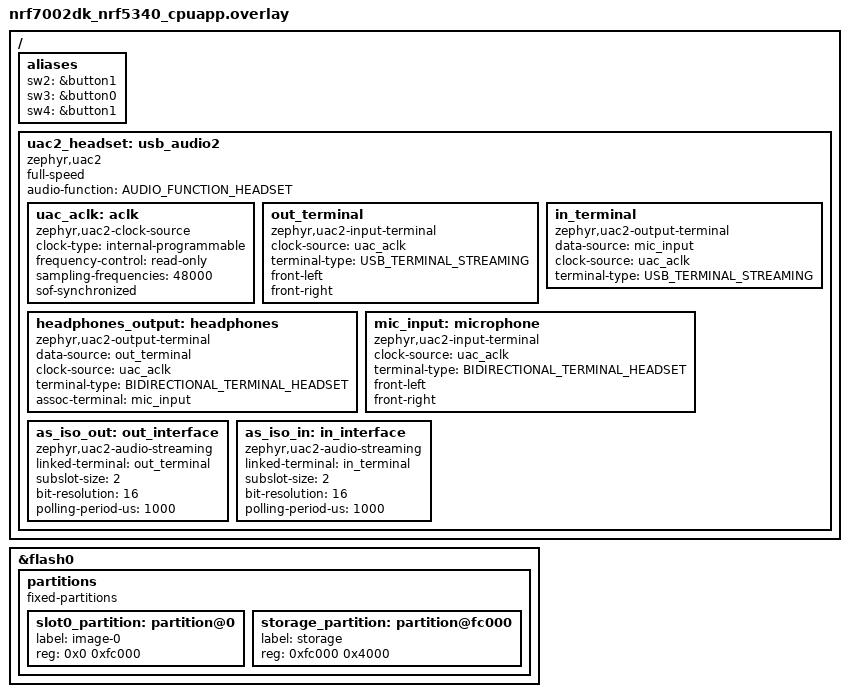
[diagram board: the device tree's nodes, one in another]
/*
 * Copyright (c) 2025 Nordic Semiconductor ASA
 *
 * SPDX-License-Identifier: LicenseRef-Nordic-5-Clause
 */

#include <dt-bindings/usb/audio.h>

/* nRF7002DK has only 2 buttons (sw0, sw1). Map the extra button aliases
 * required by button_assignments.h to the existing buttons so the
 * build compiles; at runtime only two physical buttons are usable.
 */
/ {
	aliases {
		sw2 = &button1;
		sw3 = &button0;
		sw4 = &button1;
	};
};

/* UAC2 (USB Audio Class 2.0) headset device — required by audio_usb.c
 * (DT_NODELABEL(uac2_headset)). Full-Speed on the nRF5340 usbd controller.
 */
/ {
	uac2_headset: usb_audio2 {
		compatible = "zephyr,uac2";
		status = "okay";
		full-speed;
		audio-function = <AUDIO_FUNCTION_HEADSET>;

		uac_aclk: aclk {
			compatible = "zephyr,uac2-clock-source";
			clock-type = "internal-programmable";
			frequency-control = "read-only";
			sampling-frequencies = <48000>;
			sof-synchronized;
		};

		out_terminal: out_terminal {
			compatible = "zephyr,uac2-input-terminal";
			clock-source = <&uac_aclk>;
			terminal-type = <USB_TERMINAL_STREAMING>;
			front-left;
			front-right;
		};

		headphones_output: headphones {
			compatible = "zephyr,uac2-output-terminal";
			data-source = <&out_terminal>;
			clock-source = <&uac_aclk>;
			terminal-type = <BIDIRECTIONAL_TERMINAL_HEADSET>;
			assoc-terminal = <&mic_input>;
		};

		in_terminal: in_terminal {
			compatible = "zephyr,uac2-output-terminal";
			data-source = <&mic_input>;
			clock-source = <&uac_aclk>;
			terminal-type = <USB_TERMINAL_STREAMING>;
		};

		mic_input: microphone {
			compatible = "zephyr,uac2-input-terminal";
			clock-source = <&uac_aclk>;
			terminal-type = <BIDIRECTIONAL_TERMINAL_HEADSET>;
			front-left;
			front-right;
		};

		as_iso_out: out_interface {
			compatible = "zephyr,uac2-audio-streaming";
			linked-terminal = <&out_terminal>;
			subslot-size = <2>;
			bit-resolution = <16>;
			polling-period-us = <1000>;
		};

		as_iso_in: in_interface {
			compatible = "zephyr,uac2-audio-streaming";
			linked-terminal = <&in_terminal>;
			subslot-size = <2>;
			bit-resolution = <16>;
			polling-period-us = <1000>;
		};
	};
};

/* Single-image (no MCUboot) partition layout for nRF7002DK (nRF5340, 1 MB flash).
 * slot0_partition : 0x000000 - 0x0fbfff  (1008 KB, app image)
 * storage_partition: 0x0fc000 - 0x0fffff  (16 KB, NVS/settings)
 */
&flash0 {
	/delete-node/ partitions;

	partitions {
		compatible = "fixed-partitions";
		#address-cells = <1>;
		#size-cells = <1>;

		slot0_partition: partition@0 {
			label = "image-0";
			reg = <0x0 0xfc000>;
		};

		storage_partition: partition@fc000 {
			label = "storage";
			reg = <0xfc000 0x4000>;
		};
	};
};
